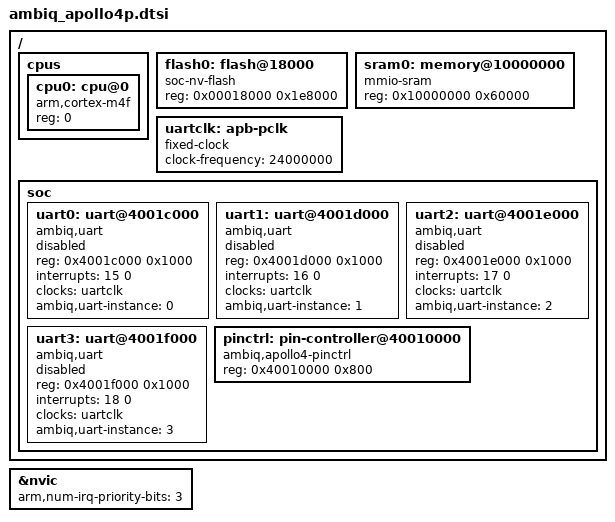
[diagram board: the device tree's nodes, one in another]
/* SPDX-License-Identifier: Apache-2.0 */

#include <arm/armv7-m.dtsi>
#include <mem.h>

/ {
	cpus {
		#address-cells = <1>;
		#size-cells = <0>;

		cpu0: cpu@0 {
			compatible = "arm,cortex-m4f";
			reg = <0>;
		};
	};

	// MRAM region
	flash0: flash@18000 {
		compatible = "soc-nv-flash";
		reg = <0x00018000 0x1e8000>;
	};

	// TCM region
	sram0: memory@10000000 {
		compatible = "mmio-sram";
		reg = <0x10000000 0x60000>;
	};

	uartclk: apb-pclk {
		compatible = "fixed-clock";
		clock-frequency = <24000000>;
		#clock-cells = <0>;
	};

	soc {
		uart0: uart@4001c000 {/* UART0 */
			compatible = "ambiq,uart", "arm,pl011";
			reg = <0x4001c000 0x1000>;
			interrupts = <15 0>;
			interrupt-names = "UART0";
			status = "disabled";
			clocks = <&uartclk>;
			ambiq,uart-instance = <0>;
		};

		uart1: uart@4001d000 {/* UART1 */
			compatible = "ambiq,uart", "arm,pl011";
			reg = <0x4001d000 0x1000>;
			interrupts = <16 0>;
			interrupt-names = "UART1";
			status = "disabled";
			clocks = <&uartclk>;
			ambiq,uart-instance = <1>;
		};

		uart2: uart@4001e000 {/* UART2 */
			compatible = "ambiq,uart", "arm,pl011";
			reg = <0x4001e000 0x1000>;
			interrupts = <17 0>;
			interrupt-names = "UART2";
			status = "disabled";
			clocks = <&uartclk>;
			ambiq,uart-instance = <2>;
		};

		uart3: uart@4001f000 {/* UART3 */
			compatible = "ambiq,uart", "arm,pl011";
			reg = <0x4001f000 0x1000>;
			interrupts = <18 0>;
			interrupt-names = "UART3";
			status = "disabled";
			clocks = <&uartclk>;
			ambiq,uart-instance = <3>;
		};

		pinctrl: pin-controller@40010000 {
			compatible = "ambiq,apollo4-pinctrl";
			reg = <0x40010000 0x800>;
		};
	};
};

&nvic {
	arm,num-irq-priority-bits = <3>;
};
